AUTOSAR XML (schema 00050)
package /ComponentTypes
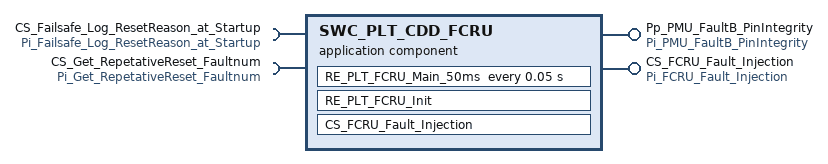
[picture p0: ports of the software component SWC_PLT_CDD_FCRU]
  application sw component type SWC_PLT_CDD_FCRU
    provide port Pp_PMU_FaultB_PinIntegrity: nonqueued-sender-com-spec{data-element=De_PMU_FaultB_PinIntegrityStat, init-value=0}, provided-interface=Pi_PMU_FaultB_PinIntegrity
    provide port CS_FCRU_Fault_Injection: server-com-spec{operation=Read, queue-length=1}, provided-interface=Pi_FCRU_Fault_Injection
    require port CS_Failsafe_Log_ResetReason_at_Startup: client-com-spec=fcru_reset_reason, required-interface=Pi_Failsafe_Log_ResetReason_at_Startup
    require port CS_Get_RepetativeReset_Faultnum: client-com-spec=Operation, required-interface=Pi_Get_RepetativeReset_Faultnum
    behavior SWC_PLT_CDD_FCRU_InternalBehavior: handle-termination-and-restart=NO-SUPPORT
      timing event TMT_RE_PLT_FCRU_Main_50ms: start-on-event=RE_PLT_FCRU_Main_50ms, period=0.05
      init event SWC_PLT_CDD_FCRU_InitEvent: start-on-event=RE_PLT_FCRU_Init
      operation invoked event OIT_CS_FCRU_Fault_Injection_Read_CS_FCRU_Fault_Injection_Read: start-on-event=CS_FCRU_Fault_Injection, operation=CS_FCRU_Fault_Injection.Read
      runnable RE_PLT_FCRU_Main_50ms
        sync call SC_CS_Failsafe_Log_ResetReason_at_Startup_fcru_reset_reason: operation=CS_Failsafe_Log_ResetReason_at_Startup.fcru_reset_reason
      runnable RE_PLT_FCRU_Init
        data-send-points:
          access SEND_Pp_PMU_FaultB_PinIntegrity_De_PMU_FaultB_PinIntegrityStat: accessed-variable=Pp_PMU_FaultB_PinIntegrity.De_PMU_FaultB_PinIntegrityStat
        sync call SC_CS_Get_RepetativeReset_Faultnum_Operation: operation=CS_Get_RepetativeReset_Faultnum.Operation
      runnable CS_FCRU_Fault_Injection
  swc implementation SWC_PLT_CDD_FCRU_Implementation: behavior=SWC_PLT_CDD_FCRU_InternalBehavior
